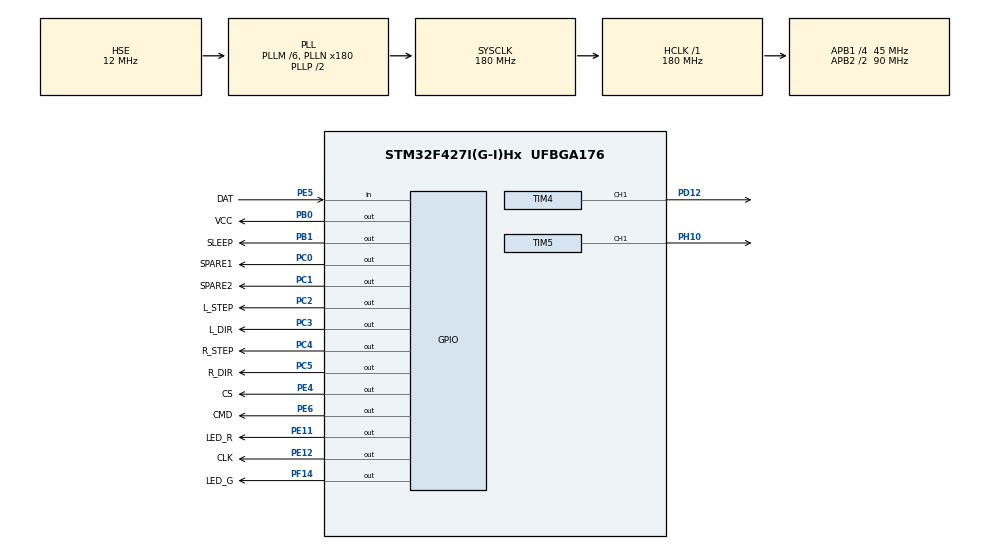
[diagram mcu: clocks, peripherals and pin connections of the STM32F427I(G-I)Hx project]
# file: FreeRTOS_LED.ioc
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FREERTOS.Tasks01=RC_Task,24,128,Start_RC_Task,Default,NULL,Dynamic,NULL,NULL;Motor_Task,40,128,Start_Motor_Task,Default,NULL,Dynamic,NULL,NULL;Ctr_Task,8,128,Start_Ctr_Task,Default,NULL,Dynamic,NULL,NULL
Mcu.Family=STM32F4
Mcu.Name=STM32F427I(G-I)Hx
Mcu.Package=UFBGA176
NVIC.PriorityGroup=NVIC_PRIORITYGROUP_4
PA13.Mode=Serial_Wire
PA13.Signal=SYS_JTMS-SWDIO
PA14.Mode=Serial_Wire
PA14.Signal=SYS_JTCK-SWCLK
PB0.GPIO_Label=VCC
PB0.Signal=GPIO_Output
PB1.GPIO_Label=SLEEP
PB1.Signal=GPIO_Output
PC0.GPIO_Label=SPARE1
PC0.Signal=GPIO_Output
PC1.GPIO_Label=SPARE2
PC1.Signal=GPIO_Output
PC2.GPIO_Label=L_STEP
PC2.Signal=GPIO_Output
PC3.GPIO_Label=L_DIR
PC3.Signal=GPIO_Output
PC4.GPIO_Label=R_STEP
PC4.Signal=GPIO_Output
PC5.GPIO_Label=R_DIR
PC5.Signal=GPIO_Output
PD12.GPIO_ModeDefaultPP=GPIO_MODE_AF_PP
PD12.Signal=S_TIM4_CH1
PE11.GPIO_Label=LED_R
PE11.Signal=GPIO_Output
PE12.GPIO_Label=CLK
PE12.Signal=GPIO_Output
PE4.GPIO_Label=CS
PE4.Signal=GPIO_Output
PE5.GPIO_Label=DAT
PE5.Signal=GPIO_Input
PE6.GPIO_Label=CMD
PE6.Signal=GPIO_Output
PF14.GPIO_Label=LED_G
PF14.Signal=GPIO_Output
PH0/OSC_IN.Mode=HSE-External-Oscillator
PH0/OSC_IN.Signal=RCC_OSC_IN
PH1/OSC_OUT.Mode=HSE-External-Oscillator
PH1/OSC_OUT.Signal=RCC_OSC_OUT
PH10.Signal=S_TIM5_CH1
ProjectManager.HeapSize=0x200
ProjectManager.StackSize=0x400
ProjectManager.TargetToolchain=CMake
RCC.48MHZClocksFreq_Value=90000000
RCC.AHBFreq_Value=180000000
RCC.APB1CLKDivider=RCC_HCLK_DIV4
RCC.APB1Freq_Value=45000000
RCC.APB1TimFreq_Value=90000000
RCC.APB2CLKDivider=RCC_HCLK_DIV2
RCC.APB2Freq_Value=90000000
RCC.APB2TimFreq_Value=180000000
RCC.CortexFreq_Value=180000000
RCC.HCLKFreq_Value=180000000
RCC.HSE_VALUE=12000000
RCC.HSI_VALUE=16000000
RCC.LSE_VALUE=32768
RCC.PLLM=6
RCC.PLLN=180
RCC.PLLSourceVirtual=RCC_PLLSOURCE_HSE
RCC.SYSCLKFreq_VALUE=180000000
RCC.SYSCLKSource=RCC_SYSCLKSOURCE_PLLCLK
RCC.VCOOutputFreq_Value=360000000
SH.S_TIM4_CH1.0=TIM4_CH1,PWM Generation1 CH1
SH.S_TIM5_CH1.0=TIM5_CH1,PWM Generation1 CH1
TIM4.AutoReloadPreload=TIM_AUTORELOAD_PRELOAD_ENABLE
TIM4.Channel-PWM\ Generation1\ CH1=TIM_CHANNEL_1
TIM4.Period=200-1
TIM4.Prescaler=89
TIM4.Pulse-PWM\ Generation1\ CH1=50
TIM5.AutoReloadPreload=TIM_AUTORELOAD_PRELOAD_ENABLE
TIM5.Channel-PWM\ Generation1\ CH1=TIM_CHANNEL_1
TIM5.Period=200-1
TIM5.Prescaler=89
TIM5.Pulse-PWM\ Generation1\ CH1=50
VP_FREERTOS_VS_CMSIS_V2.Mode=CMSIS_V2
VP_TIM4_VS_ClockSourceINT.Mode=Internal
VP_TIM5_VS_ClockSourceINT.Mode=Internal
board=custom

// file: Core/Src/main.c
/* USER CODE BEGIN Header */
/**
  ******************************************************************************
  * @file           : main.c
  * @brief          : Main program body
  ******************************************************************************
  * @attention
  *
  * Copyright (c) 2025 STMicroelectronics.
  * All rights reserved.
  *
  * This software is licensed under terms that can be found in the LICENSE file
  * in the root directory of this software component.
  * If no LICENSE file comes with this software, it is provided AS-IS.
  *
  ******************************************************************************
  */
/* USER CODE END Header */
#include "main.h"
#include "cmsis_os.h"
#include "delay.h"
#include "ax_ps2.h"
#include "motor.h"

JOYSTICK_TypeDef my_joystick;

TIM_HandleTypeDef htim4;
TIM_HandleTypeDef htim5;

/* Definitions for RC_Task */
osThreadId_t RC_TaskHandle;
const osThreadAttr_t RC_Task_attributes = {
  .name = "RC_Task",
  .stack_size = 128 * 4,
  .priority = (osPriority_t) osPriorityNormal,
};
/* Definitions for Motor_Task */
osThreadId_t Motor_TaskHandle;
const osThreadAttr_t Motor_Task_attributes = {
  .name = "Motor_Task",
  .stack_size = 128 * 4,
  .priority = (osPriority_t) osPriorityHigh,
};
/* Definitions for Ctr_Task */
osThreadId_t Ctr_TaskHandle;
const osThreadAttr_t Ctr_Task_attributes = {
  .name = "Ctr_Task",
  .stack_size = 128 * 4,
  .priority = (osPriority_t) osPriorityLow,
};

void SystemClock_Config(void);
static void MX_GPIO_Init(void);
static void MX_TIM4_Init(void);
static void MX_TIM5_Init(void);
void Start_RC_Task(void *argument);
void Start_Motor_Task(void *argument);
void Start_Ctr_Task(void *argument);

int main(void)
{

  /* MCU Configuration--------------------------------------------------------*/

  /* Reset of all peripherals, Initializes the Flash interface and the Systick. */
  HAL_Init();

  /* Configure the system clock */
  SystemClock_Config();

  /* Initialize all configured peripherals */
  MX_GPIO_Init();
  MX_TIM4_Init();
  MX_TIM5_Init();
  /* USER CODE BEGIN 2 */
  DWT_Delay_Init();
  /* USER CODE END 2 */

  /* Init scheduler */
  osKernelInitialize();
  HAL_TIM_PWM_Start(&htim4, TIM_CHANNEL_1);
  HAL_TIM_PWM_Start(&htim5, TIM_CHANNEL_1);

  /* Create the thread(s) */
  /* creation of RC_Task */
  RC_TaskHandle = osThreadNew(Start_RC_Task, NULL, &RC_Task_attributes);

  /* creation of Motor_Task */
  Motor_TaskHandle = osThreadNew(Start_Motor_Task, NULL, &Motor_Task_attributes);

  /* creation of Ctr_Task */
  Ctr_TaskHandle = osThreadNew(Start_Ctr_Task, NULL, &Ctr_Task_attributes);

  /* Start scheduler */
  osKernelStart();

  /* We should never get here as control is now taken by the scheduler */

  /* Infinite loop */
  while (1)
  {

  }
}

void SystemClock_Config(void)
{
  RCC_OscInitTypeDef RCC_OscInitStruct = {0};
  RCC_ClkInitTypeDef RCC_ClkInitStruct = {0};

  /** Configure the main internal regulator output voltage
  */
  __HAL_RCC_PWR_CLK_ENABLE();
  __HAL_PWR_VOLTAGESCALING_CONFIG(PWR_REGULATOR_VOLTAGE_SCALE1);

  /** Initializes the RCC Oscillators according to the specified parameters
  * in the RCC_OscInitTypeDef structure.
  */
  RCC_OscInitStruct.OscillatorType = RCC_OSCILLATORTYPE_HSE;
  RCC_OscInitStruct.HSEState = RCC_HSE_ON;
  RCC_OscInitStruct.PLL.PLLState = RCC_PLL_ON;
  RCC_OscInitStruct.PLL.PLLSource = RCC_PLLSOURCE_HSE;
  RCC_OscInitStruct.PLL.PLLM = 6;
  RCC_OscInitStruct.PLL.PLLN = 180;
  RCC_OscInitStruct.PLL.PLLP = RCC_PLLP_DIV2;
  RCC_OscInitStruct.PLL.PLLQ = 4;
  if (HAL_RCC_OscConfig(&RCC_OscInitStruct) != HAL_OK)
  {
    Error_Handler();
  }

  /** Activate the Over-Drive mode
  */
  if (HAL_PWREx_EnableOverDrive() != HAL_OK)
  {
    Error_Handler();
  }

  /** Initializes the CPU, AHB and APB buses clocks
  */
  RCC_ClkInitStruct.ClockType = RCC_CLOCKTYPE_HCLK|RCC_CLOCKTYPE_SYSCLK
                              |RCC_CLOCKTYPE_PCLK1|RCC_CLOCKTYPE_PCLK2;
  RCC_ClkInitStruct.SYSCLKSource = RCC_SYSCLKSOURCE_PLLCLK;
  RCC_ClkInitStruct.AHBCLKDivider = RCC_SYSCLK_DIV1;
  RCC_ClkInitStruct.APB1CLKDivider = RCC_HCLK_DIV4;
  RCC_ClkInitStruct.APB2CLKDivider = RCC_HCLK_DIV2;

  if (HAL_RCC_ClockConfig(&RCC_ClkInitStruct, FLASH_LATENCY_5) != HAL_OK)
  {
    Error_Handler();
  }
}

static void MX_TIM4_Init(void)
{

  TIM_ClockConfigTypeDef sClockSourceConfig = {0};
  TIM_MasterConfigTypeDef sMasterConfig = {0};
  TIM_OC_InitTypeDef sConfigOC = {0};

  htim4.Instance = TIM4;
  htim4.Init.Prescaler = 89;
  htim4.Init.CounterMode = TIM_COUNTERMODE_UP;
  htim4.Init.Period = 200-1;
  htim4.Init.ClockDivision = TIM_CLOCKDIVISION_DIV1;
  htim4.Init.AutoReloadPreload = TIM_AUTORELOAD_PRELOAD_ENABLE;
  if (HAL_TIM_Base_Init(&htim4) != HAL_OK)
  {
    Error_Handler();
  }
  sClockSourceConfig.ClockSource = TIM_CLOCKSOURCE_INTERNAL;
  if (HAL_TIM_ConfigClockSource(&htim4, &sClockSourceConfig) != HAL_OK)
  {
    Error_Handler();
  }
  if (HAL_TIM_PWM_Init(&htim4) != HAL_OK)
  {
    Error_Handler();
  }
  sMasterConfig.MasterOutputTrigger = TIM_TRGO_RESET;
  sMasterConfig.MasterSlaveMode = TIM_MASTERSLAVEMODE_DISABLE;
  if (HAL_TIMEx_MasterConfigSynchronization(&htim4, &sMasterConfig) != HAL_OK)
  {
    Error_Handler();
  }
  sConfigOC.OCMode = TIM_OCMODE_PWM1;
  sConfigOC.Pulse = 50;
  sConfigOC.OCPolarity = TIM_OCPOLARITY_HIGH;
  sConfigOC.OCFastMode = TIM_OCFAST_DISABLE;
  if (HAL_TIM_PWM_ConfigChannel(&htim4, &sConfigOC, TIM_CHANNEL_1) != HAL_OK)
  {
    Error_Handler();
  }
  HAL_TIM_MspPostInit(&htim4);

}

static void MX_TIM5_Init(void)
{

  TIM_ClockConfigTypeDef sClockSourceConfig = {0};
  TIM_MasterConfigTypeDef sMasterConfig = {0};
  TIM_OC_InitTypeDef sConfigOC = {0};

  htim5.Instance = TIM5;
  htim5.Init.Prescaler = 89;
  htim5.Init.CounterMode = TIM_COUNTERMODE_UP;
  htim5.Init.Period = 200-1;
  htim5.Init.ClockDivision = TIM_CLOCKDIVISION_DIV1;
  htim5.Init.AutoReloadPreload = TIM_AUTORELOAD_PRELOAD_ENABLE;
  if (HAL_TIM_Base_Init(&htim5) != HAL_OK)
  {
    Error_Handler();
  }
  sClockSourceConfig.ClockSource = TIM_CLOCKSOURCE_INTERNAL;
  if (HAL_TIM_ConfigClockSource(&htim5, &sClockSourceConfig) != HAL_OK)
  {
    Error_Handler();
  }
  if (HAL_TIM_PWM_Init(&htim5) != HAL_OK)
  {
    Error_Handler();
  }
  sMasterConfig.MasterOutputTrigger = TIM_TRGO_RESET;
  sMasterConfig.MasterSlaveMode = TIM_MASTERSLAVEMODE_DISABLE;
  if (HAL_TIMEx_MasterConfigSynchronization(&htim5, &sMasterConfig) != HAL_OK)
  {
    Error_Handler();
  }
  sConfigOC.OCMode = TIM_OCMODE_PWM1;
  sConfigOC.Pulse = 50;
  sConfigOC.OCPolarity = TIM_OCPOLARITY_HIGH;
  sConfigOC.OCFastMode = TIM_OCFAST_DISABLE;
  if (HAL_TIM_PWM_ConfigChannel(&htim5, &sConfigOC, TIM_CHANNEL_1) != HAL_OK)
  {
    Error_Handler();
  }
  HAL_TIM_MspPostInit(&htim5);

}

static void MX_GPIO_Init(void)
{
  GPIO_InitTypeDef GPIO_InitStruct = {0};

  /* GPIO Ports Clock Enable */
  __HAL_RCC_GPIOA_CLK_ENABLE();
  __HAL_RCC_GPIOE_CLK_ENABLE();
  __HAL_RCC_GPIOH_CLK_ENABLE();
  __HAL_RCC_GPIOC_CLK_ENABLE();
  __HAL_RCC_GPIOD_CLK_ENABLE();
  __HAL_RCC_GPIOB_CLK_ENABLE();
  __HAL_RCC_GPIOF_CLK_ENABLE();

  /*Configure GPIO pin Output Level */
  HAL_GPIO_WritePin(GPIOE, CS_Pin|CMD_Pin|LED_R_Pin|CLK_Pin, GPIO_PIN_RESET);

  /*Configure GPIO pin Output Level */
  HAL_GPIO_WritePin(GPIOC, SPARE1_Pin|SPARE2_Pin|L_STEP_Pin|L_DIR_Pin
                          |R_STEP_Pin|R_DIR_Pin, GPIO_PIN_RESET);

  /*Configure GPIO pin Output Level */
  HAL_GPIO_WritePin(GPIOB, VCC_Pin, GPIO_PIN_SET);
    HAL_GPIO_WritePin(GPIOB, SLEEP_Pin, GPIO_PIN_RESET);

  /*Configure GPIO pin Output Level */
  HAL_GPIO_WritePin(LED_G_GPIO_Port, LED_G_Pin, GPIO_PIN_RESET);

  /*Configure GPIO pins : CS_Pin CMD_Pin LED_R_Pin CLK_Pin */
  GPIO_InitStruct.Pin = CS_Pin|CMD_Pin|LED_R_Pin|CLK_Pin;
  GPIO_InitStruct.Mode = GPIO_MODE_OUTPUT_PP;
  GPIO_InitStruct.Pull = GPIO_NOPULL;
  GPIO_InitStruct.Speed = GPIO_SPEED_FREQ_LOW;
  HAL_GPIO_Init(GPIOE, &GPIO_InitStruct);

  /*Configure GPIO pin : DAT_Pin */
  GPIO_InitStruct.Pin = DAT_Pin;
  GPIO_InitStruct.Mode = GPIO_MODE_INPUT;
  GPIO_InitStruct.Pull = GPIO_NOPULL;
  HAL_GPIO_Init(DAT_GPIO_Port, &GPIO_InitStruct);

  /*Configure GPIO pins : SPARE1_Pin SPARE2_Pin L_STEP_Pin L_DIR_Pin
                           R_STEP_Pin R_DIR_Pin */
  GPIO_InitStruct.Pin = SPARE1_Pin|SPARE2_Pin|L_STEP_Pin|L_DIR_Pin
                          |R_STEP_Pin|R_DIR_Pin;
  GPIO_InitStruct.Mode = GPIO_MODE_OUTPUT_PP;
  GPIO_InitStruct.Pull = GPIO_NOPULL;
  GPIO_InitStruct.Speed = GPIO_SPEED_FREQ_LOW;
  HAL_GPIO_Init(GPIOC, &GPIO_InitStruct);

  /*Configure GPIO pins : SLEEP_Pin VCC_Pin */
  GPIO_InitStruct.Pin = SLEEP_Pin|VCC_Pin;
  GPIO_InitStruct.Mode = GPIO_MODE_OUTPUT_PP;
  GPIO_InitStruct.Pull = GPIO_NOPULL;
  GPIO_InitStruct.Speed = GPIO_SPEED_FREQ_LOW;
  HAL_GPIO_Init(GPIOB, &GPIO_InitStruct);

  /*Configure GPIO pin : LED_G_Pin */
  GPIO_InitStruct.Pin = LED_G_Pin;
  GPIO_InitStruct.Mode = GPIO_MODE_OUTPUT_PP;
  GPIO_InitStruct.Pull = GPIO_NOPULL;
  GPIO_InitStruct.Speed = GPIO_SPEED_FREQ_LOW;
  HAL_GPIO_Init(LED_G_GPIO_Port, &GPIO_InitStruct);

}

void Start_RC_Task(void *argument)
{
  /* USER CODE BEGIN 5 */
  /* Infinite loop */
  for(;;)
  {
      AX_PS2_ScanKey(&my_joystick);
      osDelay(50);
      HAL_GPIO_TogglePin(LED_G_GPIO_Port,LED_G_Pin);
      osDelay(1);
  }
  /* USER CODE END 5 */
}

void Start_Motor_Task(void *argument)
{
  /* USER CODE BEGIN Start_Motor_Task */
  /* Infinite loop */
  for(;;)
  {
      drive_motor(my_joystick.btn1);
      HAL_GPIO_TogglePin(LED_R_GPIO_Port,LED_R_Pin);
      osDelay(1);
  }
  /* USER CODE END Start_Motor_Task */
}

void Start_Ctr_Task(void *argument)
{
  for(;;)
  {
    osDelay(1);
  }
}

void Error_Handler(void)
{
  __disable_irq();
  while (1)
  {
  }
}
